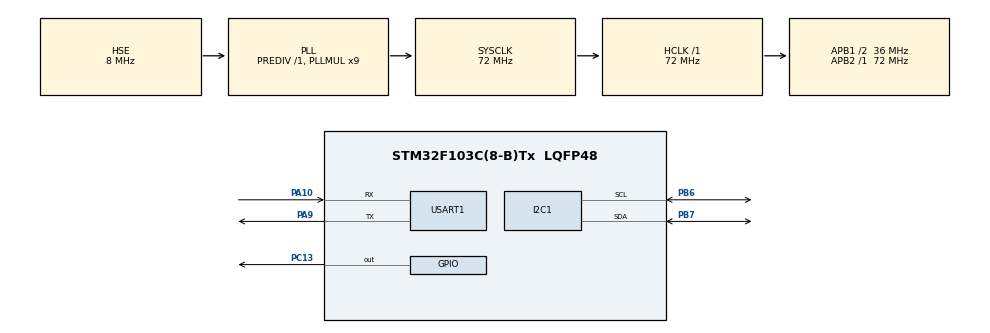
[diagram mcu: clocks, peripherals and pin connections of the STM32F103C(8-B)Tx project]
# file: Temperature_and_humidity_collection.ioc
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Dma.I2C1_RX.1.Direction=DMA_PERIPH_TO_MEMORY
Dma.I2C1_RX.1.Instance=DMA1_Channel7
Dma.I2C1_RX.1.MemDataAlignment=DMA_MDATAALIGN_BYTE
Dma.I2C1_RX.1.MemInc=DMA_MINC_ENABLE
Dma.I2C1_RX.1.Mode=DMA_NORMAL
Dma.I2C1_RX.1.PeriphDataAlignment=DMA_PDATAALIGN_BYTE
Dma.I2C1_RX.1.PeriphInc=DMA_PINC_DISABLE
Dma.I2C1_RX.1.Priority=DMA_PRIORITY_LOW
Dma.I2C1_TX.0.Direction=DMA_MEMORY_TO_PERIPH
Dma.I2C1_TX.0.Instance=DMA1_Channel6
Dma.I2C1_TX.0.MemDataAlignment=DMA_MDATAALIGN_BYTE
Dma.I2C1_TX.0.MemInc=DMA_MINC_ENABLE
Dma.I2C1_TX.0.Mode=DMA_NORMAL
Dma.I2C1_TX.0.PeriphDataAlignment=DMA_PDATAALIGN_BYTE
Dma.I2C1_TX.0.PeriphInc=DMA_PINC_DISABLE
Dma.I2C1_TX.0.Priority=DMA_PRIORITY_LOW
Dma.Request0=I2C1_TX
Dma.Request1=I2C1_RX
I2C1.I2C_Mode=I2C_Standard
Mcu.Family=STM32F1
Mcu.Name=STM32F103C(8-B)Tx
Mcu.Package=LQFP48
NVIC.DMA1_Channel6_IRQn=true\:0\:0\:false\:false\:true\:false\:true\:true
NVIC.DMA1_Channel7_IRQn=true\:0\:0\:false\:false\:true\:false\:true\:true
NVIC.I2C1_EV_IRQn=true\:0\:0\:false\:false\:true\:true\:true\:true
NVIC.PriorityGroup=NVIC_PRIORITYGROUP_4
PA10.Mode=Asynchronous
PA10.Signal=USART1_RX
PA13.Mode=Serial_Wire
PA13.Signal=SYS_JTMS-SWDIO
PA14.Mode=Serial_Wire
PA14.Signal=SYS_JTCK-SWCLK
PA9.Mode=Asynchronous
PA9.Signal=USART1_TX
PB6.Mode=I2C
PB6.Signal=I2C1_SCL
PB7.Mode=I2C
PB7.Signal=I2C1_SDA
PC13-TAMPER-RTC.Signal=GPIO_Output
PD0-OSC_IN.Mode=HSE-External-Oscillator
PD0-OSC_IN.Signal=RCC_OSC_IN
PD1-OSC_OUT.Mode=HSE-External-Oscillator
PD1-OSC_OUT.Signal=RCC_OSC_OUT
ProjectManager.HeapSize=0x200
ProjectManager.StackSize=0x400
ProjectManager.TargetToolchain=MDK-ARM V5.32
RCC.AHBFreq_Value=72000000
RCC.APB1CLKDivider=RCC_HCLK_DIV2
RCC.APB1Freq_Value=36000000
RCC.APB1TimFreq_Value=72000000
RCC.APB2Freq_Value=72000000
RCC.APB2TimFreq_Value=72000000
RCC.HCLKFreq_Value=72000000
RCC.PLLMUL=RCC_PLL_MUL9
RCC.PLLSourceVirtual=RCC_PLLSOURCE_HSE
RCC.SYSCLKFreq_VALUE=72000000
RCC.SYSCLKSource=RCC_SYSCLKSOURCE_PLLCLK
RCC.USBFreq_Value=72000000
USART1.VirtualMode=VM_ASYNC
board=custom

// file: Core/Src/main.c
/* USER CODE BEGIN Header */
/**
  ******************************************************************************
  * @file           : main.c
  * @brief          : Main program body
  ******************************************************************************
  * @attention
  *
  * Copyright (c) 2022 STMicroelectronics.
  * All rights reserved.
  *
  * This software is licensed under terms that can be found in the LICENSE file
  * in the root directory of this software component.
  * If no LICENSE file comes with this software, it is provided AS-IS.
  *
  ******************************************************************************
  */
/* USER CODE END Header */
#include "main.h"
#include "dma.h"
#include "i2c.h"
#include "usart.h"
#include "gpio.h"

/* USER CODE BEGIN Includes */
#include<stdio.h>
#include "AHT20-21_DEMO_V1_3.h"
/* USER CODE END Includes */

/* USER CODE BEGIN PTD */
int fputc(int ch,FILE *f)
{
    HAL_UART_Transmit(&huart1,(uint8_t *)&ch,1,0xFFFF);
		//等待发送结束
		while(__HAL_UART_GET_FLAG(&huart1,UART_FLAG_TC)!=SET){
		}

    return ch;
}
/* USER CODE END PTD */

void SystemClock_Config(void);

int main(void)
{
  /* USER CODE BEGIN 1 */
	uint32_t CT_data[2]={0,0};
	volatile int  c1,t1;
	Delay_1ms(500);
  /* USER CODE END 1 */

  /* MCU Configuration--------------------------------------------------------*/

  /* Reset of all peripherals, Initializes the Flash interface and the Systick. */
  HAL_Init();

  /* Configure the system clock */
  SystemClock_Config();

  /* Initialize all configured peripherals */

  MX_USART1_UART_Init();
  MX_DMA_Init();
  MX_I2C1_Init();
  MX_USART1_UART_Init();

  /* USER CODE BEGIN 2 */
  AHT20_Init();
	Delay_1ms(500);

  /* USER CODE END 2 */

  /* Infinite loop */
  while (1)
  {
		//AHT20_Read_CTdata(CT_data);       //不经过CRC校验，直接读取AHT20的温度和湿度数据    推荐每隔大于1S读一次
		AHT20_Read_CTdata_crc(CT_data);  //crc校验后，读取AHT20的温度和湿度数据

		c1 = CT_data[0]*1000/1024/1024;  //计算得到湿度值c1（放大了10倍）
		t1 = CT_data[1]*2000/1024/1024-500;//计算得到温度值t1（放大了10倍）
		printf("正在检测");
		HAL_Delay(100);
		printf(".");
		HAL_Delay(100);
		printf(".");
		HAL_Delay(100);
		printf(".");
		HAL_Delay(100);
		printf(".");
		HAL_Delay(100);
		printf(".");
		HAL_Delay(100);
		printf(".");
		HAL_Delay(100);
		printf(".");
		HAL_Delay(100);
		printf(".");
		HAL_Delay(100);
		printf(".");
		HAL_Delay(100);
		printf(".");
		printf("\r\n");
		HAL_Delay(1000);
		printf("温度:%d%d.%d",t1/100,(t1/10)%10,t1%10);
		printf("湿度:%d%d.%d",c1/100,(c1/10)%10,c1%10);
		printf("\r\n");
		printf("等待");
		HAL_Delay(100);
		printf(".");
		HAL_Delay(100);
		printf(".");
		HAL_Delay(100);
		printf(".");
		HAL_Delay(100);
		printf(".");
		HAL_Delay(100);
		printf(".");
		HAL_Delay(100);
		printf(".");
		HAL_Delay(100);
		printf(".");
		HAL_Delay(100);
		printf(".");
		HAL_Delay(100);
		printf(".");
		HAL_Delay(100);
		printf(".");
		printf("\r\n");
		HAL_Delay(1000);
  }
}

void SystemClock_Config(void)
{
  RCC_OscInitTypeDef RCC_OscInitStruct = {0};
  RCC_ClkInitTypeDef RCC_ClkInitStruct = {0};

  /** Initializes the RCC Oscillators according to the specified parameters
  * in the RCC_OscInitTypeDef structure.
  */
  RCC_OscInitStruct.OscillatorType = RCC_OSCILLATORTYPE_HSE;
  RCC_OscInitStruct.HSEState = RCC_HSE_ON;
  RCC_OscInitStruct.HSEPredivValue = RCC_HSE_PREDIV_DIV1;
  RCC_OscInitStruct.HSIState = RCC_HSI_ON;
  RCC_OscInitStruct.PLL.PLLState = RCC_PLL_ON;
  RCC_OscInitStruct.PLL.PLLSource = RCC_PLLSOURCE_HSE;
  RCC_OscInitStruct.PLL.PLLMUL = RCC_PLL_MUL9;
  if (HAL_RCC_OscConfig(&RCC_OscInitStruct) != HAL_OK)
  {
    Error_Handler();
  }

  /** Initializes the CPU, AHB and APB buses clocks
  */
  RCC_ClkInitStruct.ClockType = RCC_CLOCKTYPE_HCLK|RCC_CLOCKTYPE_SYSCLK
                              |RCC_CLOCKTYPE_PCLK1|RCC_CLOCKTYPE_PCLK2;
  RCC_ClkInitStruct.SYSCLKSource = RCC_SYSCLKSOURCE_PLLCLK;
  RCC_ClkInitStruct.AHBCLKDivider = RCC_SYSCLK_DIV1;
  RCC_ClkInitStruct.APB1CLKDivider = RCC_HCLK_DIV2;
  RCC_ClkInitStruct.APB2CLKDivider = RCC_HCLK_DIV1;

  if (HAL_RCC_ClockConfig(&RCC_ClkInitStruct, FLASH_LATENCY_2) != HAL_OK)
  {
    Error_Handler();
  }
}

void Error_Handler(void)
{
  __disable_irq();
  while (1)
  {
  }
}
